# NM1230_v1 register map
File version: 1.0
Registers are 32-bit, read-write, reset 0x0 unless marked. A register's access mark holds for its fields unless they carry their own. Offsets are from the block's base; [hi:lo] are bit positions; {n}, {i} and the like mark numbered series; 'fields as' and 'values as' point back to an identical list.

## ADC — ADC Register Map
Base 0x400E0000
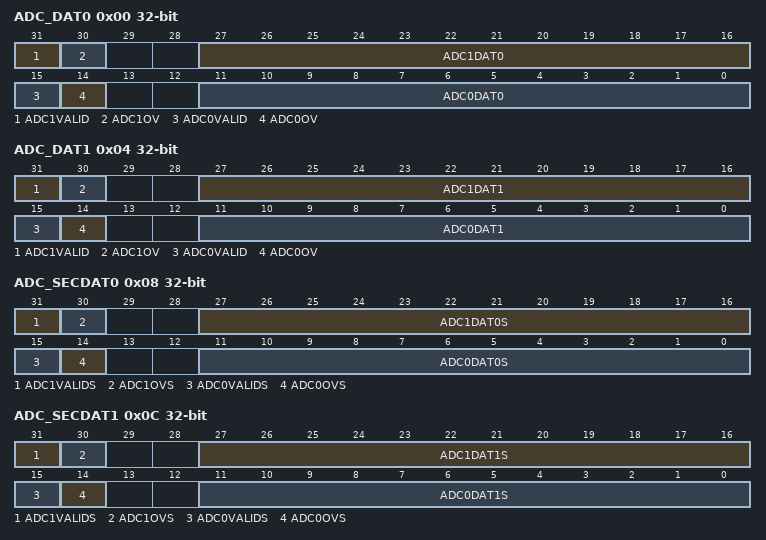
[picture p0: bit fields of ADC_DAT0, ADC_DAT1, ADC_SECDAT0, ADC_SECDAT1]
0x00 ADC_DAT0 ro — ADC Data Register 0
  [31] ADC1VALID — ADC1 Valid Flag. Note: This bit is set to '1' when A/D conversion is completed and cleared by hardware after the ADC_DAT0 register is read.
    0=Data in ADC1DAT0[27:16] bits not valid; 1=Data in ADC1DAT0[27:16] bits valid
  [30] ADC1OV — ADC1 over Run Flag. Note1: If converted data in ADC1DAT0[27:16] has not been read before, the new conversion result is loaded to this register, OV is set to '1'. Note2:It is cleared by hardware after the ADC_DAT0 register is read.
    0=Data in ADC1DAT0[27:16] is recent conversion result; 1=Data in ADC1DAT0[27:16] overwritten
  [27:16] ADC1DAT0 — ADC1 Conversion Result. This field contains conversion result of ADC.
  [15] ADC0VALID — ADC0 Valid Flag. Note: This bit is set to '1' when A/D conversion is completed and cleared by hardware after the ADC_DAT0 register is read.
    0=Data in ADC0DAT0[11:0] bits not valid; 1=Data in ADC0DAT0[11:0] bits valid
  [14] ADC0OV — ADC0 over Run Flag. Note1: If converted data in ADC0DAT0[11:0] has not been read before the new conversion result is loaded to this register, OV is set to '1'. Note2: It is cleared by hardware after the ADC_DAT0 register is read.
    0=Data in ADC0DAT0[11:0] is recent conversion result; 1=Data in ADC0DAT0[11:0] overwritten
  [11:0] ADC0DAT0 — ADC0 Conversion Result. This field contains conversion result of ADC.
0x04 ADC_DAT1 ro — ADC Data Register 1
  [31] ADC1VALID — ADC1 Valid Flag. Note: This bit is set to '1' when A/D conversion is completed and cleared by hardware after the ADC_DAT1 register is read.
    0=Data in ADC1DAT1[27:16] bits not valid; 1=Data in ADC1DAT1[27:16] bits valid
  [30] ADC1OV — ADC1 over Run Flag. Note1: If converted data in ADC1DAT1[27:16] has not been read before the new conversion result is loaded to this register, OV is set to '1'. Note2: It is cleared by hardware after the ADC_DAT1 register is read.
    0=Data in ADC1DAT1[27:16] is recent conversion result; 1=Data in ADC1DAT1[27:16] overwritten
  [27:16] ADC1DAT1 — ADC1 Conversion Result for FIFO1. This field contains conversion result of ADC.
  [15] ADC0VALID — ADC0 Valid Flag. Note: This bit is set to '1' when A/D conversion is completed and cleared by hardware after the ADC_DAT1 register is read.
    0=Data in ADC0DAT1[11:0] bits not valid; 1=Data in ADC0DAT1[11:0] bits valid
  [14] ADC0OV — ADC0Over Run Flag. Note1: If converted data in ADC0DAT1[11:0] has not been read before the new conversion result is loaded to this register, OV is set to '1'. Note2: It is cleared by hardware after the ADC_DAT1 register is read.
    0=Data in ADC0DAT1[11:0] is recent conversion result; 1=Data in ADC0DAT1[11:0]] overwritten
  [11:0] ADC0DAT1 — ADC0 Conversion Result for FIFO1. This field contains conversion result of ADC.
0x08 ADC_SECDAT0 ro — ADC Data Register 0 for Secondary Trigger
  [31] ADC1VALIDS — ADC1 By Secondary Trigger Valid Flag. Note: This bit is set to '1' when A/D conversion is completed and cleared by hardware after the ADC_SECDAT0 register is read.
    0=Data in ADC_SECDAT0 [27:16] bits not valid; 1=Data in ADC_SECDAT0 [27:16] bits valid
  [30] ADC1OVS — Secondary ADC1 By Secondary Trigge over Run Flag. Note1: If converted data in ADC_SECDAT0 [27:16] has not been read before, the new conversion result is loaded to this register, OV is set to '1'. Note2:It is cleared by hardware after the ADC_SECDAT0 register is read.
    0=Data in ADC_SECDAT0 [27:16] is recent conversion result; 1=Data in ADC_SECDAT0 [27:16] overwritten
  [27:16] ADC1DAT0S — Secondary ADC1 By Secondary Trigge Conversion Result. This field contains conversion result of ADC.
  [15] ADC0VALIDS — Secondary ADC0 By Secondary Trigge Valid Flag. Note: This bit is set to '1' when A/D conversion is completed and cleared by hardware after the ADC_SECDAT0 register is read.
    0=Data in ADC_SECDAT0 [11:0] bits not valid; 1=Data in ADC_SECDAT0 [11:0] bits valid
  [14] ADC0OVS — Secondary ADC0 By Secondary Trigge over Run Flag. Note1: If converted data in ADC_SECDAT0 [11:0] has not been read before the new conversion result is loaded to this register, OV is set to '1'. Note2: It is cleared by hardware after the ADC_SECDAT0 register is read.
    0=Data in ADC_SECDAT0 [11:0] is recent conversion result; 1=Data in ADC_SECDAT0 [11:0] overwritten
  [11:0] ADC0DAT0S — Secondary ADC0 By Secondary Trigge Conversion Result. This field contains conversion result of ADC.
0x0C ADC_SECDAT1 ro — ADC Data Register 1 for Secondary Trigger
  [31] ADC1VALIDS — ADC1 By Secondary Trigge Valid Flag. Note: This bit is set to '1' when A/D conversion is completed and cleared by hardware after the ADC_SECDAT1 register is read.
    0=Data in ADC_SECDAT1[27:16] bits not valid; 1=Data in ADC_SECDAT1 [27:16] bits valid
  [30] ADC1OVS — ADC1 By Secondary Trigge over Run Flag. Note1: If converted data in ADC_SECDAT1 [27:16] has not been read before the new conversion result is loaded to this register, OV is set to '1'. Note2: It is cleared by hardware after the ADC_SECDAT1 register is read.
    0=Data in ADC_SECDAT1 [27:16] is recent conversion result; 1=Data in ADC_SECDAT1 [27:16] overwritten
  [27:16] ADC1DAT1S — ADC1 By Secondary Trigge Conversion Result for FIFO1. This field contains conversion result of ADC.
  [15] ADC0VALIDS — ADC0 By Secondary Trigge Valid Flag. Note: This bit is set to '1' when A/D conversion is completed and cleared by hardware after the ADC_SECDAT1 register is read.
    0=Data in ADC_SECDAT1 [11:0] bits not valid; 1=Data in ADC_SECDAT1 [11:0] bits valid
  [14] ADC0OVS — ADC0 By Secondary Trigge Over Run Flag. Note1: If converted data in ADC_SECDAT1 [11:0] has not been read before the new conversion result is loaded to this register, OV is set to '1'. Note2: It is cleared by hardware after the ADC_SECDAT1 register is read.
    0=Data in ADC_SECDAT1 [11:0] is recent conversion result; 1=Data in ADC_SECDAT1 [11:0] overwritten
  [11:0] ADC0DAT1S — ADC0 Conversion Result for FIFO1. This field contains conversion result of ADC.
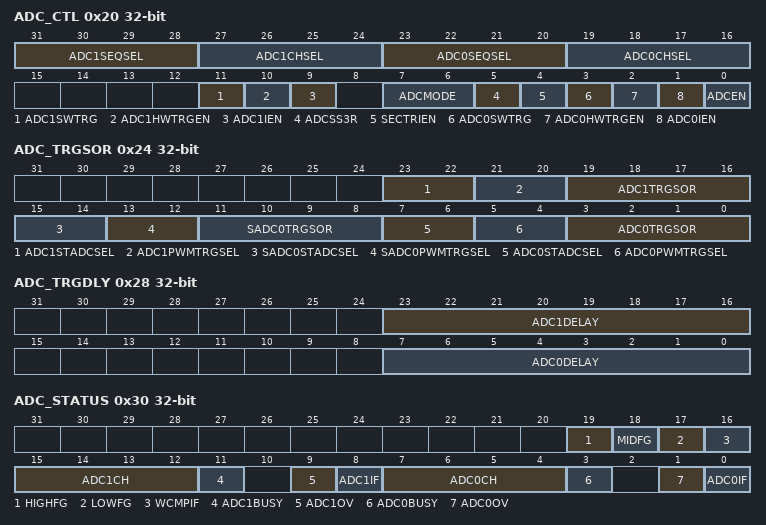
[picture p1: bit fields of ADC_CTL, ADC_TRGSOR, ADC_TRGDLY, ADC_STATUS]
0x20 ADC_CTL — ADC Control Register
  [31:28] ADC1SEQSEL
    0=ADC1_CH0. (PB.4); 1=ADC1_CH1. (PD.2); 2=ADC1_CH2. (PC.2); 3=ADC0_CH0. (PB.0); 4=ADC0_CH4. (PC.1); 5=PGA_ADC; 6=Temp Sensor; 7=VSS; 8=OP0. (PC.4); 9=OP1. (PE.2); 10=OP2. (PE.5); 11=ADC1_CH3. (PF.3); 12=ADC1_CH4. (PF.4); 13=ADC1_CH5. (PC.5); 14=ADC1_CH6. (PC.6); 15=ADC1_CH7. (PC.7)
  [27:24] ADC1CHSEL — ADC1 Channel Select
    values as ADC1SEQSEL
  [23:20] ADC0SEQSEL
    0=ADC0_CH0. (PB.0); 1=ADC0_CH1. (PB.1); 2=ADC0_CH2. (PB.2); 3=ADC0_CH3. (PC.0); 4=ADC0_CH4. (PC.1); 5=PGA_ADC; 6=BAND_GAP. (BG 1.2V); 7=VSS; 8=OP0. (PC.4); 9=OP1. (PE.2); 10=OP2. (PE.5); 11=DAC0; 12=DAC1; 13=ADC0_CH5. (PB.5); 14=ADC0_CH6. (PB.6); 15=ADC0_CH7. (PB.7)
  [19:16] ADC0CHSEL — ADC1 Channel Select
    values as ADC0SEQSEL
  [11] ADC1SWTRG — ADC1 Conversion Start. Note: ADC1SWTRG will be set to '1' when any of ADC1 trigger event happen or user also can write '1' to this bit to demand a software ADC1 trigger, when hardware finish of this ADC conversion request it will cleared to '0' automatically.
    0=Conversion stopped and A/D converter entered idle state; 1=Indicate there has ADC1 conversion request
  [10] ADC1HWTRGEN — Hardware Trigger ADC Convertion Enable Control. Enable or disable triggering of A/D conversion by Hardware (PWM, Timer, ADC self)
    0=Hardware Trigger ADC Convertion Disabled; 1=Hardware Trigger ADC Convertion Enabled
  [9] ADC1IEN — ADC1 Interrupt Enable Control. Note: A/D conversion end interrupt request is generated if ADC1IEN bit is set to '1'.
    0=ADC1 interrupt function Disabled; 1=ADC1 interrupt function Enabled
  [7:6] ADCMODE — A/D Conversion Mode
    0=Independent simple; independent function and independent interrupt by themselves; 1=Independent 2SH; independent trigger function, ADC0 with ADC1 both convert finish then only generate interrupt ADC0IF; 2=Simultaneous Simple; simultaneous trigger function by ADC0, ADC0 with ADC1 both convert finish then generate interrupt ADC0IF; 3=Simultaneous Sequential; simultaneous trigger function by ADC0, this mode converts sequential is ADC0 - ADC1 -ADC0 - ADC1 4 times, then generate interrupt ADC0IF
  [5] ADCSS3R
    0=convert sequential is ADC0 - ADC1 - ADC0 - ADC1, four datas at ADCMODE=11; 1=convert sequential is ADC0 - ADC1 - ADC0, three datas at ADCMODE=11
  [4] SECTRIEN — Secondary Trigger enable
    0=Disable ADC Secondary trigger function; 1=Enable Secondary triger even to trigger ADC, this register only effect on simultaneous mode
  [3] ADC0SWTRG — ADC0 Conversion Start. Note: ADC0SWTRG will be set to '1' when any of ADC0 trigger event happen or user also can write '1' to this bit to demand a software ADC0 trigger, when hardware finish of this ADC conversion request it will cleared to '0' automatically.
    0=Conversion stopped and A/D converter entered idle state; 1=Indicate there has ADC0 conversion request
  [2] ADC0HWTRGEN — Hardware Trigger ADC Convertion Enable. Enable or disable triggering of A/D conversion by Hardware (PWM, Timer, ADC self)
    0=Disabled; 1=Enabled
  [1] ADC0IEN — ADC0 Interrupt Enable. Note: A/D conversion end interrupt request is generated if ADC0IEN bit is set to '1'.
    0=ADC0 interrupt function Disabled; 1=ADC0 interrupt function Enabled
  [0] ADCEN — ADC Converter Enable. Note: Before starting the A/D conversion function, this bit should be set to '1'. Clear it to '0' to disable A/D converter analog circuit power consumption.
    0=ADC Converter Disabled; 1=ADC Converter Enabled
0x24 ADC_TRGSOR — ADC Hardware Trigger Source Control Register
  [23:22] ADC1STADCSEL — ADC1 External Trigger Pin (STADC) Trigger Selection
    0=Rising; 1=Falling; 2=Rising or Falling
  [21:20] ADC1PWMTRGSEL — PWM Trigger Selection for ADC1
    0=EPWM Signal Falling. (Not available in edge-aligned type); 1=EPWM Counter Central. (Not available in edge-aligned type); 2=EPWM signal Rising; 3=Period
  [19:16] ADC1TRGSOR — ADC1 Trigger Source
    0=STADC; {v}=PWM{v-1} (v=1..6); 7=TMR0_MATCH; 8=TMR1_MATCH; 9=ECAPPHG_TRG. (From ECAP, CPAEN (CAPTF0| CAPTF1| CAPTF2); 10=ADC0IF; 11=ADC1IF
  [15:14] SADC0STADCSEL — ADC0 External Trigger Pin (STADC) Trigger Selection, Use For Secondary Trigger.
    0=Rising; 1=Falling; 2=Rising or Falling
  [13:12] SADC0PWMTRGSEL — PWM Trigger Selection for ADC0, Use For Secondary Trigger.
    0=EPWM Signal Falling; 1=EPWM Counter Central; 2=EPWM signal Rising; 3=Period
  [11:8] SADC0TRGSOR — ADC0 Trigger Source, Use For Secondaryary Trigger.
    values as ADC1TRGSOR
  [7:6] ADC0STADCSEL — ADC0 External Trigger Pin (STADC) Trigger Selection
    0=Rising; 1=Falling; 2=Rising or Falling
  [5:4] ADC0PWMTRGSEL — PWM Trigger Selection for ADC0
    values as ADC1PWMTRGSEL
  [3:0] ADC0TRGSOR — ADC0 Trigger Source
    values as ADC1TRGSOR
0x28 ADC_TRGDLY — ADC Trigger Delay Control Register
  [23:16] ADC1DELAY — ADC1 Trigger Delay Timer. Setting this field will delay ADC start conversion time after ADCxTRGCTL trigger is coming. (x:0/1). Delay time is (4 * ADC1DELAY) * system clock
  [7:0] ADC0DELAY — ADC0 Trigger Delay Timer. Setting this field will delay ADC start conversion time after ADCxTRGCTL trigger is coming. (x:0/1). Delay time is (4 * ADC0DELAY) * system clock
0x2C ADC_SMPCNT reset 0x5 — ADC Sampling Time Counter Register
  [3:0] ADCSMPCNT — ADC Sampling Counter. ADC sampling counters are 6 ADC clock is suggestion for normal channel, but ADC sampling counters are 512 ADC clock is suggestion for BAND_GAP and Temp Sensor channel
    {v}={v+1} * ADC Clock (v=0..7); 8=16 * ADC Clock; 9=32 * ADC Clock; 10=64 * ADC Clock; 11=128 * ADC Clock; 12=256 * ADC Clock; 13=512 * ADC Clock; 14=1024 * ADC Clock; 15=1024 * ADC Clock
0x30 ADC_STATUS
  [19] HIGHFG — Window Comparator High Bound Flag. When A/D conversion result higher than the setting condition in High Bound (WCMPHIGHDAT), this bit is set to '1'. Then it is cleared by writing '1' to ifself.
    0=Conversion result in ADC_DAT1 does not meet the WCMPHIGHDAT setting; 1=Conversion result in ADC_DAT1 meets the WCMPHIGHDAT setting
  [18] MIDFG — Window Comparator Middle Bound Flag. When A/D conversion result is between High Bound (WCMPHIGHDAT) and Low Bound (WCMPLOWDAT), this bit is set to '1'. Then it is cleared by writing '1' to ifself.
    0=Conversion result in ADC_DAT1 isn't between High Bound (WCMPHIGHDAT) and Low Bound (WCMPLOWDAT); 1=Conversion result in ADC_DAT1 is between High Bound (WCMPHIGHDAT) and Low Bound (WCMPLOWDAT)
  [17] LOWFG — Window Comparator Low Bound Flag. When A/D conversion result lower than the setting condition in Low Bound (WCMPLOWDAT), this bit is set to '1'. Then it is cleared by writing '1' to ifself.
    0=Conversion result in ADC_DAT1 does not meet the WCMPLOWDAT setting; 1=Conversion result in ADC_DAT1 meets the WCMPLOWDAT setting
  [16] WCMPIF — Window Comparator Interrupt Flag. When Windows Comparator has generat a result output, this bit is set to '1'. Then it is cleared by writing '1' to ifself.
    0=Conversion result in ADC_DAT1 does not meets the WCMPLOWDAT setting; 1=Conversion result in ADC_DAT1 meets the WCMPLOWDAT setting
  [15:12] ADC1CH — Current Conversion Channel. It is read only.
  [11] ADC1BUSY — BUSY/IDLE
    0=A/D converter is in idle state; 1=A/D converter is busy at conversion
  [9] ADC1OV — Over Run Flag. It is a mirror to OV bit in ADDR.
  [8] ADC1IF — ADC1 Conversion End Flag. A status flag that indicates the end of A/D conversion. ADF is set to '1' When A/D conversion ends. This flag can be cleared by writing '1' to itself.
  [7:4] ADC0CH — Current Conversion Channel. It is read only.
  [3] ADC0BUSY — BUSY/IDLE
    values as ADC1BUSY
  [1] ADC0OV — Over Run Flag. It is a mirror to OV bit in ADDR.
  [0] ADC0IF — A/D Conversion End Flag. A status flag that indicates the end of A/D conversion. ADF is set to '1' When A/D conversion ends. This flag can be cleared by writing '1' to itself.
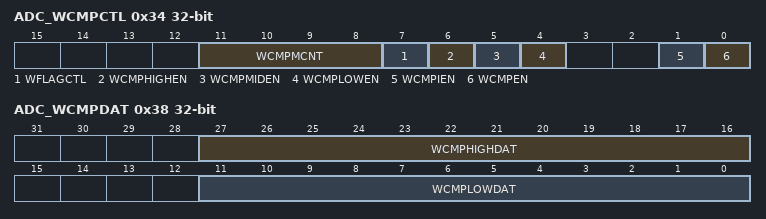
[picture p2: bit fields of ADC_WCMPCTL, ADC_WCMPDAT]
0x34 ADC_WCMPCTL — ADC Window Comparator Control Register
  [11:8] WCMPMCNT — Window Compare Match Count. When the A/D conversion result matches the compare condition defined by CMP Flag setting (CMPUPEN, CMPEQUEN, CMPLOWEN and WCFLAGCTL), the internal match counter will increase 1, otherwise, the compare matuch counter will be clear to 0. When the compare result meets the setting, compare match counter will increase 1, otherwise, the compare match counter will be clear to 0. When the match counter reaches the setting of (WCMPMCNT+1) then WCMPIF bit will be set
  [7] WFLAGCTL — Window Comparator Flag Control. When the A/D conversion result matches the compare condition
    0=Auto-update; 1=none
  [6] WCMPHIGHEN — Window Comparator High Flag Enable Control set A/D conversion result higher than compare condition High bound range
    0=Window Comparator High Flag Disabled; 1=Window Comparator High Flag Enabled
  [5] WCMPMIDEN — Window Comparator Middle Flag Enable Control set A/D conversion result equal to compare condition at Low and High bound range
    0=Window Comparator Middle Flag Disabled; 1=Window Comparator Middle Flag Enabled
  [4] WCMPLOWEN — Window Comparator Low Flag Enable Control set A/D conversion result lower than compare condition Low bound range
    0=Window Comparator Low Flag Disabled; 1=Window Comparator Low Flag Enabled
  [1] WCMPIEN — Window Comparator Interrupt Enable Control
    0=Window Comparator Interrupt Disabled; 1=Window Comparator Interrupt Enabled
  [0] WCMPEN — Window Comparator Enable Control
    0=Window Comparator Disabled; 1=Window Comparator Enabled
0x38 ADC_WCMPDAT — ADC Window Comparator Data Register
  [27:16] WCMPHIGHDAT — Window Comparator High Bound Data
  [11:0] WCMPLOWDAT — Window Comparator Low Bound Data
